AUTOSAR XML (schema 4-3-0)
package /ComponentTypes
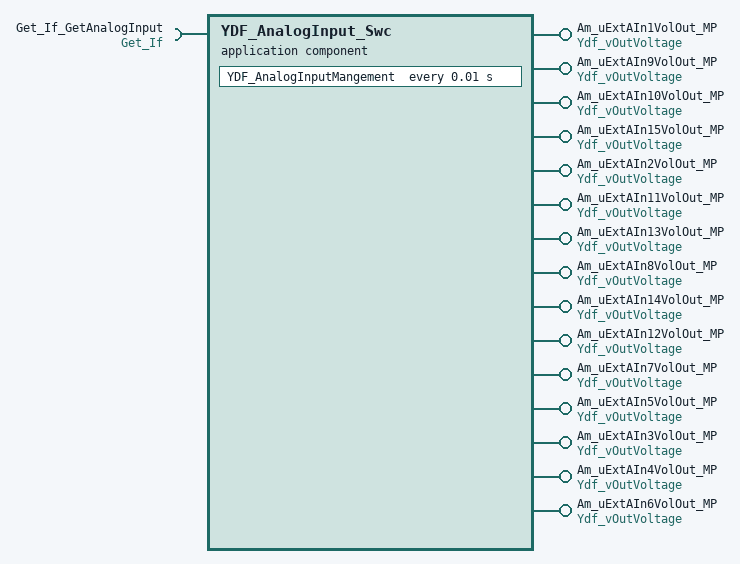
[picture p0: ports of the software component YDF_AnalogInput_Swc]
  application sw component type YDF_AnalogInput_Swc
    4 x provide port, all with nonqueued-sender-com-spec{data-element=OutVoltage, init-value=0}, provided-interface=Ydf_vOutVoltage:
      Am_uExtAIn1VolOut_MP
      Am_uExtAIn9VolOut_MP
      Am_uExtAIn10VolOut_MP
      Am_uExtAIn15VolOut_MP
    require port Get_If_GetAnalogInput: required-interface=Get_If
      required-com-specs:
        Get_Ad_Result
        Get_io_inResult
        Get_BTS_OutResult
        Get_CAN_ActiveInf
        Icu_17_GtmCcu6_PWMIN_CH{1..4}
        Icu_17_GtmCcu6_PWMIN_PWMSCB1
        Icu_17_GtmCcu6_PWMIN_PWMSCB2
        Icu_17_GtmCcu6_PWMIN_LAMPSCB1
        Icu_17_GtmCcu6_PWMIN_LAMPSCB2
        Get_Bottom_Ver
        Get_SentData
        Get_Level_OutResult
        Get_PwmOrLevel_OutResult
        Get_Motor_OutResult
    11 x provide port, all with nonqueued-sender-com-spec{data-element=OutVoltage, init-value=0}, provided-interface=Ydf_vOutVoltage:
      Am_uExtAIn2VolOut_MP
      Am_uExtAIn11VolOut_MP
      Am_uExtAIn13VolOut_MP
      Am_uExtAIn8VolOut_MP
      Am_uExtAIn14VolOut_MP
      Am_uExtAIn12VolOut_MP
      Am_uExtAIn7VolOut_MP
      Am_uExtAIn5VolOut_MP
      Am_uExtAIn3VolOut_MP
      Am_uExtAIn4VolOut_MP
      Am_uExtAIn6VolOut_MP
    behavior YDF_AnalogInput_Swc_InternalBehavior
      timing event TMT_YDF_AnalogInputMangement: start-on-event=YDF_AnalogInputMangement, period=0.01
      runnable YDF_AnalogInputMangement
        data-send-points:
          15 x access:
            SEND_Am_uExtAIn10VolOut_MP_OutVoltage: accessed-variable=Am_uExtAIn10VolOut_MP.OutVoltage
            SEND_Am_uExtAIn15VolOut_MP_OutVoltage: accessed-variable=Am_uExtAIn15VolOut_MP.OutVoltage
            SEND_Am_uExtAIn1VolOut_MP_OutVoltage: accessed-variable=Am_uExtAIn1VolOut_MP.OutVoltage
            SEND_Am_uExtAIn9VolOut_MP_OutVoltage: accessed-variable=Am_uExtAIn9VolOut_MP.OutVoltage
            SEND_Am_uExtAIn{11..14}VolOut_MP_OutVoltage: accessed-variable=Am_uExtAIn{11..14}VolOut_MP.OutVoltage
            SEND_Am_uExtAIn{2..8}VolOut_MP_OutVoltage: accessed-variable=Am_uExtAIn{2..8}VolOut_MP.OutVoltage
        sync call SC_Get_If_GetAnalogInput_Get_Ad_Result: operation=Get_If_GetAnalogInput.Get_Ad_Result
  swc implementation YDF_AnalogInput_Swc_Implementation: behavior=YDF_AnalogInput_Swc_InternalBehavior
